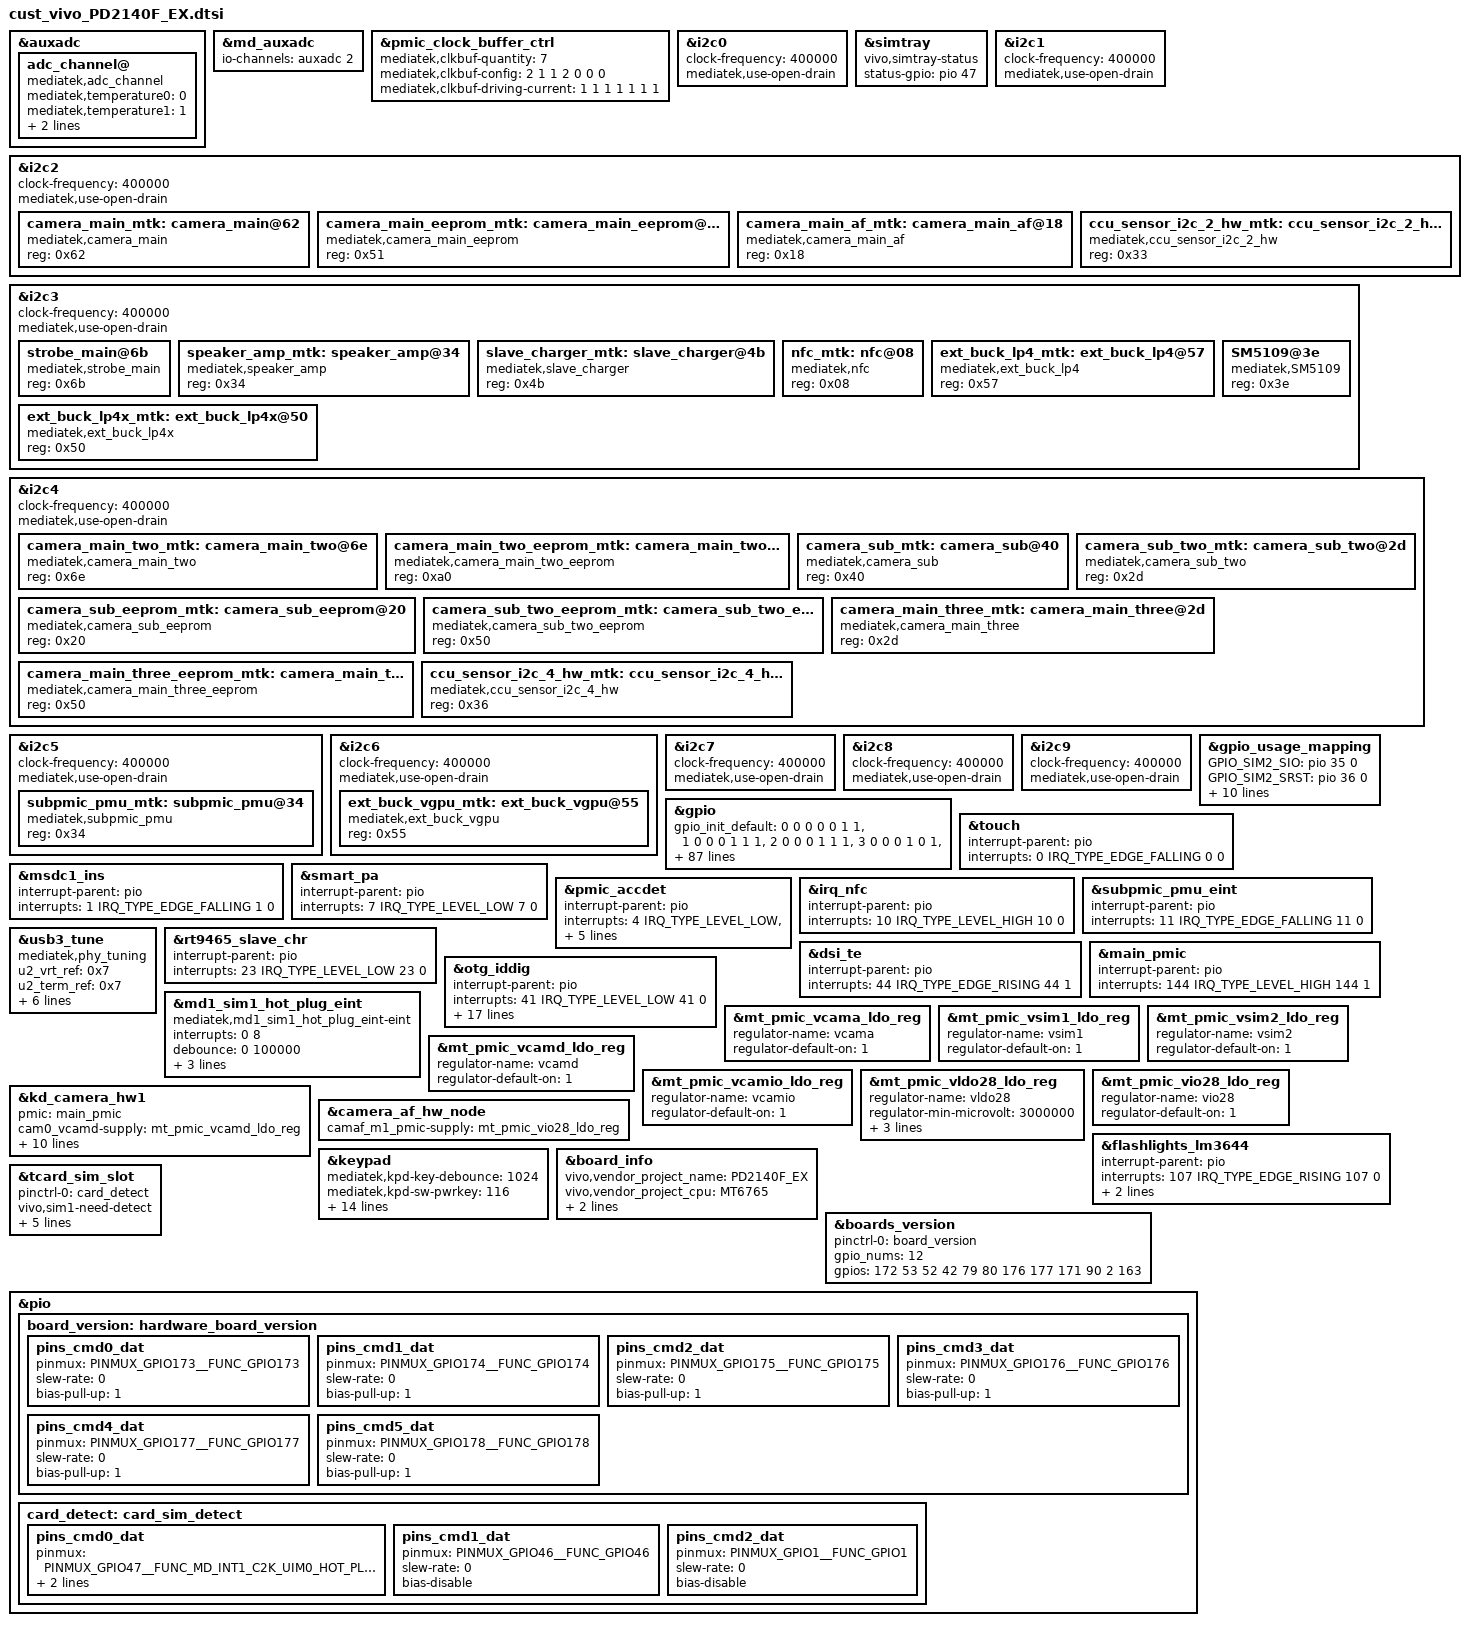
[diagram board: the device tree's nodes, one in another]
/*
 * Generated by MTK SP DrvGen Version: 3.5.160809 for MT6765.
 * 2020-11-06 15:12:15
 * Do Not Modify The File.
 * Copyright Mediatek Inc. (c) 2016.
*/

/*************************
 * ADC DTSI File
*************************/

&auxadc {
	adc_channel@ {
		compatible = "mediatek,adc_channel";
		mediatek,temperature0 = <0>;
		mediatek,temperature1 = <1>;
		mediatek,adc_fdd_rf_params_dynamic_custom_ch = <2>;
		status = "okay";
	};
};
&md_auxadc {
	io-channels = <&auxadc 2>;
};


/*************************
 * CLK_BUF DTSI File
*************************/

&pmic_clock_buffer_ctrl {
	mediatek,clkbuf-quantity = <7>;
	mediatek,clkbuf-config = <2 1 1 2 0 0 0>;
	mediatek,clkbuf-driving-current = <1 1 1 1 1 1 1>;
	status = "okay";
};


/*************************
 * I2C DTSI File
*************************/

&i2c0 {
	#address-cells = <1>;
	#size-cells = <0>;
	clock-frequency = <400000>;
	mediatek,use-open-drain;
};
&simtray {
	compatible = "vivo,simtray-status";
	status-gpio = <&pio 47 0x00>;
};
&i2c1 {
	#address-cells = <1>;
	#size-cells = <0>;
	clock-frequency = <400000>;
	mediatek,use-open-drain;
};

&i2c2 {
	#address-cells = <1>;
	#size-cells = <0>;
	clock-frequency = <400000>;
	mediatek,use-open-drain;
/*	camera_main_mtk:camera_main@46 {
		compatible = "mediatek,camera_main";
		reg = <0x46>;
		status = "okay";
	};
*/
	camera_main_mtk:camera_main@62 {
		compatible = "mediatek,camera_main";
		reg = <0x62>;
		status = "okay";
	};

	camera_main_eeprom_mtk:camera_main_eeprom@51 {
		compatible = "mediatek,camera_main_eeprom";
		reg = <0x51>;
		status = "okay";
	};
	camera_main_af_mtk:camera_main_af@18 {
		compatible = "mediatek,camera_main_af";
		reg = <0x18>;
		status = "okay";
	};

	ccu_sensor_i2c_2_hw_mtk:ccu_sensor_i2c_2_hw@33 {
		compatible = "mediatek,ccu_sensor_i2c_2_hw";
		reg = <0x33>;
		status = "okay";
	};

};

&i2c3 {
	#address-cells = <1>;
	#size-cells = <0>;
	clock-frequency = <400000>;
	mediatek,use-open-drain;

	strobe_main@6b {
	        compatible = "mediatek,strobe_main";
	        reg = <0x6b>;
	        status = "okay";
	};

	speaker_amp_mtk:speaker_amp@34 {
		compatible = "mediatek,speaker_amp";
		reg = <0x34>;
		status = "okay";
	};

	slave_charger_mtk:slave_charger@4b {
		compatible = "mediatek,slave_charger";
		reg = <0x4b>;
		status = "okay";
	};

	nfc_mtk:nfc@08 {
		compatible = "mediatek,nfc";
		reg = <0x08>;
		status = "okay";
	};

	ext_buck_lp4_mtk:ext_buck_lp4@57 {
		compatible = "mediatek,ext_buck_lp4";
		reg = <0x57>;
		status = "okay";
	};

	ext_buck_lp4x_mtk:ext_buck_lp4x@50 {
		compatible = "mediatek,ext_buck_lp4x";
		reg = <0x50>;
		status = "okay";
	};

	SM5109@3e {
		compatible = "mediatek,SM5109";
		reg = <0x3e>;
		status = "okay";
	};

};

&i2c4 {
	#address-cells = <1>;
	#size-cells = <0>;
	clock-frequency = <400000>;
	mediatek,use-open-drain;

/*		camera_sub_mtk:camera_sub@20 {
		compatible = "mediatek,camera_sub";
		reg = <0x20>;
		status = "okay";
	};
*/
	camera_main_two_mtk:camera_main_two@6e {
		compatible = "mediatek,camera_main_two";
		reg = <0x6e>;
		status = "okay";
	};
	camera_main_two_eeprom_mtk:camera_main_two_eeprom@a0 {
		compatible = "mediatek,camera_main_two_eeprom";
		reg = <0xa0>;
		status = "okay";
	};
	/*PD2140*/
	camera_sub_mtk:camera_sub@40 {
		compatible = "mediatek,camera_sub";
		reg = <0x40>;
		status = "okay";
	};
	camera_sub_eeprom_mtk:camera_sub_eeprom@20 {
		compatible = "mediatek,camera_sub_eeprom";
		reg = <0x20>;
		status = "okay";
	};
	// camera_main_two_af_mtk:camera_main_two_af@18 {
	// 	compatible = "mediatek,camera_main_two_af";
	// 	reg = <0x18>;
	// 	status = "okay";
	// };
	camera_sub_two_mtk:camera_sub_two@2d {
		compatible = "mediatek,camera_sub_two";
		reg = <0x2d>;
		status = "okay";
	};
	camera_sub_two_eeprom_mtk:camera_sub_two_eeprom@50 {
		compatible = "mediatek,camera_sub_two_eeprom";
		reg = <0x50>;
		status = "okay";
	};
	camera_main_three_mtk:camera_main_three@2d {
		compatible = "mediatek,camera_main_three";
		reg = <0x2d>;
		status = "okay";
	};
	camera_main_three_eeprom_mtk:camera_main_three_eeprom@50 {
		compatible = "mediatek,camera_main_three_eeprom";
		reg = <0x50>;
		status = "okay";
	};
	ccu_sensor_i2c_4_hw_mtk:ccu_sensor_i2c_4_hw@36 {
		compatible = "mediatek,ccu_sensor_i2c_4_hw";
		reg = <0x36>;
		status = "okay";
	};
};

&i2c5 {
	#address-cells = <1>;
	#size-cells = <0>;
	clock-frequency = <400000>;
	mediatek,use-open-drain;
	subpmic_pmu_mtk:subpmic_pmu@34 {
		compatible = "mediatek,subpmic_pmu";
		reg = <0x34>;
		status = "okay";
	};
	/*
	swithing_charger@6a {
		compatible = "mediatek,swithing_charger";
		chg_version_gpio = <&pio 173 0>;
		reg = <0x6a>;
		status = "okay";
    };
    swithing_charger_2nd@6b {
		compatible = "mediatek,swithing_charger_2nd";
		reg = <0x6b>;
		status = "okay";
    };
    slave_charger@6b {
		compatible = "mediatek,slave_charging_bq25601d";
		pinctrl-names = "slave_chg_default", "slave_chg_enable", "slave_chg_disable";
		pinctrl-0 = <&slave_chg_pins_default>;
		pinctrl-1 = <&slave_chg_pins_enable>;
		pinctrl-2 = <&slave_chg_pins_disable>;
		slave-chg-gpio = <&pio 69 0>;
		reg = <0x6b>;
		status = "okay";
    };

	usb_type_c@4e {
		compatible = "mediatek,usb_type_c";
		reg = <0x4e>;
		status = "okay";
	};*/
};

&i2c6 {
	#address-cells = <1>;
	#size-cells = <0>;
	clock-frequency = <400000>;
	mediatek,use-open-drain;


	ext_buck_vgpu_mtk:ext_buck_vgpu@55 {
		compatible = "mediatek,ext_buck_vgpu";
		reg = <0x55>;
		status = "okay";
	};

};

&i2c7 {
	#address-cells = <1>;
	#size-cells = <0>;
	clock-frequency = <400000>;
	mediatek,use-open-drain;
};

&i2c8 {
	#address-cells = <1>;
	#size-cells = <0>;
	clock-frequency = <400000>;
	mediatek,use-open-drain;
};

&i2c9 {
	#address-cells = <1>;
	#size-cells = <0>;
	clock-frequency = <400000>;
	mediatek,use-open-drain;
};



/*************************
 * GPIO DTSI File
*************************/

&gpio_usage_mapping {
	GPIO_SIM2_SIO = <&pio 35 0>;
	GPIO_SIM2_SRST = <&pio 36 0>;
	GPIO_SIM2_SCLK = <&pio 37 0>;
	GPIO_SIM1_SCLK = <&pio 38 0>;
	GPIO_SIM1_SRST = <&pio 39 0>;
	GPIO_SIM1_SIO = <&pio 40 0>;
	GPIO_SIM1_HOT_PLUG = <&pio 47 0>;
	GPIO_FDD_BAND_SUPPORT_DETECT_1ST_PIN = <&pio 172 0>;
	GPIO_FDD_BAND_SUPPORT_DETECT_2ND_PIN = <&pio 53 0>;
	GPIO_FDD_BAND_SUPPORT_DETECT_3RD_PIN = <&pio 52 0>;
	GPIO_FDD_BAND_SUPPORT_DETECT_4TH_PIN = <&pio 42 0>;
};

&gpio{
	gpio_init_default = <0 0 0 0 0 1 1>,
		<1 0 0 0 1 1 1>,
		<2 0 0 0 1 1 1>,
		<3 0 0 0 1 0 1>,
		<4 5 0 0 1 1 0>,
		<5 0 0 0 1 0 0>,
		<6 0 1 0 0 0 0>,
		<7 0 0 0 1 1 0>,
		<8 0 0 0 0 0 1>,
		<9 0 0 0 1 1 0>,
		<10 0 0 0 0 0 1>,
		<11 0 0 0 1 1 0>,
		<12 0 0 0 1 1 0>,
		<13 3 0 0 1 1 0>,
		<14 3 1 0 0 0 0>,
		<15 3 1 0 0 0 0>,
		<16 3 1 0 0 0 0>,
		<17 2 0 0 1 0 0>,
		<18 2 0 0 1 0 0>,
		<19 2 0 0 1 0 0>,
		<20 2 0 0 1 0 0>,
		<21 1 0 0 1 0 0>,
		<22 1 0 0 1 0 0>,
		<23 1 1 0 0 0 0>,
		<24 1 0 0 0 0 0>,
		<25 0 1 0 0 0 0>,
		<26 0 1 0 0 0 0>,
		<27 0 1 0 0 0 0>,
		<28 0 1 0 0 0 0>,
		<29 1 1 0 0 0 1>,
		<30 1 0 0 1 1 1>,
		<31 1 0 0 1 1 1>,
		<32 1 0 0 1 1 1>,
		<33 1 0 0 1 1 1>,
		<34 1 0 0 1 1 1>,
		<35 1 0 0 1 1 0>,
		<36 1 1 0 0 0 0>,
		<37 1 1 0 0 0 0>,
		<38 1 1 0 0 0 0>,
		<39 1 1 0 0 0 0>,
		<40 1 0 0 1 1 0>,
		<41 0 0 0 1 1 0>,
		<42 0 0 0 1 1 0>,
		<43 1 1 0 0 0 0>,
		<44 1 0 0 1 0 0>,
		<45 0 1 0 0 0 0>,
		<46 0 0 0 0 0 0>,
		<47 1 0 0 0 0 0>,
		<48 1 0 0 1 1 1>,
		<49 1 0 0 1 1 1>,
		<50 1 0 0 1 1 1>,
		<51 1 0 0 1 1 1>,
		<52 0 0 0 1 1 0>,
		<53 0 0 0 1 1 0>,
		<54 0 0 0 0 0 1>,
		<55 1 1 0 1 0 0>,
		<56 1 1 0 1 0 0>,
		<57 1 1 0 1 0 0>,
		<58 0 0 0 1 0 0>,
		<59 1 0 0 1 0 0>,
		<60 1 0 0 1 0 0>,
		<61 1 0 0 1 0 0>,
		<62 1 0 0 1 0 0>,
		<63 1 0 0 1 0 0>,
		<64 1 0 0 1 0 0>,
		<65 1 0 0 1 0 0>,
		<66 1 0 0 1 0 0>,
		<67 1 0 0 1 0 0>,
		<68 1 0 0 1 0 0>,
		<69 1 1 0 1 0 0>,
		<70 1 1 0 1 0 0>,
		<71 1 1 0 1 0 0>,
		<72 1 1 0 1 0 0>,
		<73 1 1 0 1 0 0>,
		<74 1 1 0 1 0 0>,
		<75 1 1 0 1 0 0>,
		<76 1 1 0 1 0 0>,
		<77 1 1 0 1 0 0>,
		<78 1 1 0 1 0 0>,
		<79 1 0 0 1 0 0>,
		<80 1 0 0 1 0 0>,
		<81 1 0 0 1 1 1>,
		<82 1 0 0 1 1 1>,
		<83 1 0 0 1 1 1>,
		<84 1 0 0 1 1 1>,
		<85 1 1 0 1 0 0>,
		<86 1 1 0 1 0 0>,
		<87 0 1 0 0 0 0>,
		<88 0 0 0 1 0 0>,
		<89 1 0 0 1 0 0>,
		<90 2 1 0 0 0 0>,
		<91 0 1 0 1 0 0>,
		<92 1 1 0 0 0 0>,
		<93 1 0 0 1 1 0>,
		<94 0 0 0 1 0 0>,
		<95 1 0 0 1 1 0>,
		<96 1 1 0 0 0 0>,
		<97 0 1 0 0 0 0>,
		<98 0 1 0 0 0 0>,
		<99 0 1 0 0 0 0>,
		<100 0 1 0 0 0 0>,
		<101 0 1 0 0 0 0>,
		<102 0 1 0 0 0 0>,
		<103 1 0 0 1 1 1>,
		<104 1 0 0 1 1 1>,
		<105 1 0 0 1 1 1>,
		<106 1 0 0 1 1 1>,
		<107 2 1 0 0 0 0>,
		<108 0 1 0 0 0 0>,
		<109 0 1 0 0 0 0>,
		<110 0 0 0 1 0 0>,
		<111 0 0 0 1 0 0>,
		<112 0 0 0 1 0 0>,
		<113 0 0 0 1 0 0>,
		<114 0 0 0 1 0 0>,
		<115 0 0 0 1 0 0>,
		<116 0 0 0 1 0 0>,
		<117 0 0 0 1 0 0>,
		<118 0 0 0 1 0 0>,
		<119 0 0 0 1 0 0>,
		<120 0 0 0 1 0 0>,
		<121 0 0 0 1 0 0>,
		<122 1 0 0 1 1 1>,
		<123 1 0 0 1 1 1>,
		<124 1 1 0 0 0 1>,
		<125 1 0 0 1 1 1>,
		<126 1 0 0 1 1 1>,
		<127 1 0 0 1 1 1>,
		<128 1 0 0 1 1 1>,
		<129 1 0 0 1 1 1>,
		<130 1 0 0 1 1 1>,
		<131 1 0 0 1 0 1>,
		<132 1 0 0 1 1 1>,
		<133 1 1 1 0 0 1>,
		<134 1 0 0 1 0 1>,
		<135 1 1 0 0 0 0>,
		<136 1 1 0 0 0 0>,
		<137 1 1 0 0 0 0>,
		<138 1 1 0 0 0 0>,
		<139 1 1 0 0 0 0>,
		<140 1 0 0 1 0 0>,
		<141 1 0 0 1 0 0>,
		<142 1 0 0 1 0 0>,
		<143 1 0 0 1 0 0>,
		<144 1 0 0 1 0 0>,
		<145 1 1 1 0 0 0>,
		<146 1 0 0 1 0 0>,
		<147 1 1 0 0 0 0>,
		<148 1 1 0 0 0 0>,
		<149 1 1 0 0 0 0>,
		<150 0 1 0 0 0 0>,
		<151 0 1 0 0 0 0>,
		<152 0 1 0 0 0 0>,
		<153 0 1 0 0 0 0>,
		<154 0 1 1 0 0 0>,
		<155 0 1 0 0 0 0>,
		<156 0 1 0 0 0 0>,
		<157 0 1 0 0 0 0>,
		<158 7 0 0 1 0 0>,
		<159 0 1 0 0 0 0>,
		<160 0 1 0 0 0 0>,
		<161 1 0 0 1 1 1>,
		<162 1 0 0 1 1 1>,
		<163 0 0 0 0 0 0>,
		<164 0 0 0 0 0 0>,
		<165 0 1 0 1 0 0>,
		<166 0 1 0 1 0 0>,
		<167 0 1 0 0 0 0>,
		<168 0 0 0 1 0 0>,
		<169 0 1 0 0 0 0>,
		<170 0 1 0 0 0 0>,
		<171 0 0 0 1 0 0>,
		<172 0 0 0 1 1 0>,
		<173 0 1 0 0 0 0>,
		<174 0 0 0 1 1 0>,
		<175 0 0 0 1 1 0>,
		<176 0 0 0 1 1 0>,
		<177 0 0 0 1 1 0>,
		<178 0 1 0 0 0 0>,
		<179 0 0 0 1 0 0>;
};


/*************************
 * EINT DTSI File
*************************/

#include <dt-bindings/interrupt-controller/irq.h>
#include <dt-bindings/interrupt-controller/arm-gic.h>

&touch {
	interrupt-parent = <&pio>;
	interrupts = <0 IRQ_TYPE_EDGE_FALLING 0 0>;
	status = "okay";
};

&msdc1_ins {
	interrupt-parent = <&pio>;
	interrupts = <1 IRQ_TYPE_EDGE_FALLING 1 0>;
	status = "okay";
};

#if 0 //add for fix boot failed in lk during the bringup stage
&mrdump_ext_rst {
	interrupt-parent = <&pio>;
	interrupts = <2 IRQ_TYPE_LEVEL_LOW 2 0>;
	deb-gpios = <&pio 2 0>;
	debounce = <512000>;
	status = "okay";
};
#endif

&smart_pa {
	interrupt-parent = <&pio>;
	interrupts = <7 IRQ_TYPE_LEVEL_LOW 7 0>;
	status = "okay";
};

&pmic_accdet {
	interrupt-parent = <&pio>;
	interrupts = <4 IRQ_TYPE_LEVEL_LOW>,
				 <3 IRQ_TYPE_LEVEL_LOW>;
	deb-gpios = <&pio 4 0>;
	deb-rgpios = <&pio 3 0>;
	debounce = <256000>;
	debounce1 = <256000>;
	status = "okay";
};

&irq_nfc {
	interrupt-parent = <&pio>;
	interrupts = <10 IRQ_TYPE_LEVEL_HIGH 10 0>;
	status = "okay";
};

&subpmic_pmu_eint {
	interrupt-parent = <&pio>;
	interrupts = <11 IRQ_TYPE_EDGE_FALLING 11 0>;
	status = "okay";
};

/*taozongchen add for usb start */
&usb3_tune {
	compatible = "mediatek,phy_tuning";
	u2_vrt_ref = <0x7>;
	u2_term_ref = <0x7>;
	u2_hstx_srctrl = <0x4>;
	u2_enhance = <0x3>;
	u2_vrt_ref_host = <0x4>;
	u2_term_ref_host = <0x3>;
	u2_hstx_srctrl_host = <0x4>;
	u2_enhance_host = <0x2>;
	status = "okay";
};
/* taozongchen add for usb end */

&rt9465_slave_chr {
	interrupt-parent = <&pio>;
	interrupts = <23 IRQ_TYPE_LEVEL_LOW 23 0>;
	status = "okay";
};

&dsi_te {
	interrupt-parent = <&pio>;
	interrupts = <44 IRQ_TYPE_EDGE_RISING 44 1>;
	status = "okay";
};

&main_pmic {
	interrupt-parent = <&pio>;
	interrupts = <144 IRQ_TYPE_LEVEL_HIGH 144 1>;
	status = "okay";
};

&otg_iddig {
	interrupt-parent = <&pio>;
	interrupts = <41 IRQ_TYPE_LEVEL_LOW 41 0>;
	/*debounce = <110 0>;*/
	usbid-num = <&pio 41 1>;
	mtk,otg_chip_compatible_mode;
	usbid2-num = <&pio 167 1>;
	platform-id = <&pio 171 1>;
	pinctrl-names = "iddig_default", "iddig_otg_gpio", "iddig_otg_gpio_pull_down", "otg_gpio_pull_high", "otg_gpio_pull_low", "otg_gpio_pull_in", "otg_gpio_pull1_high", "otg_gpio_pull1_low", "otg_gpio_pull1_in", "iddig_otg_init",
"otg_gpio167_pull_high", "otg_gpio167_pull_low", "otg_gpio167_pull_in";
	pinctrl-0 = <&iddig_default>;
	pinctrl-1 = <&gpio41_mode0_gpio>;
	pinctrl-2 = <&gpio41_mode0_gpio_pull_down>;
	pinctrl-3 = <&gpio165_otg_pull_high>;
	pinctrl-4 = <&gpio165_otg_pull_low>;
	pinctrl-5 = <&gpio165_otg_pull_in>;
	pinctrl-6 = <&gpio164_otg_pull1_high>;
	pinctrl-7 = <&gpio164_otg_pull1_low>;
	pinctrl-8 = <&gpio164_otg_pull1_in>;
	pinctrl-9 = <&gpio41_mode1_iddig>;

	pinctrl-10 = <&gpio167_otg_pull1_high>;
	pinctrl-11 = <&gpio167_otg_pull1_low>;
	pinctrl-12 = <&gpio167_otg_pull1_in>;
	status = "okay";
};

/*************************
 * MD1_EINT DTSI File
*************************/

&md1_sim1_hot_plug_eint {
	compatible = "mediatek,md1_sim1_hot_plug_eint-eint";
	interrupts = <0 8>;
	debounce = <0 100000>;
	dedicated = <0 0>;
	src_pin = <0 1>;
	sockettype = <0 0>;
	status = "okay";
};



/*************************
 * PMIC DTSI File
*************************/

&mt_pmic_vcama_ldo_reg {
	regulator-name = "vcama";
	regulator-default-on = <1>; /* 0:skip, 1: off, 2:on */
	status = "okay";
};
&mt_pmic_vsim1_ldo_reg {
	regulator-name = "vsim1";
	regulator-default-on = <1>; /* 0:skip, 1: off, 2:on */
	status = "okay";
};
&mt_pmic_vsim2_ldo_reg {
	regulator-name = "vsim2";
	regulator-default-on = <1>; /* 0:skip, 1: off, 2:on */
	status = "okay";
};
&mt_pmic_vcamd_ldo_reg {
	regulator-name = "vcamd";
	regulator-default-on = <1>; /* 0:skip, 1: off, 2:on */
	status = "okay";
};
&mt_pmic_vcamio_ldo_reg {
	regulator-name = "vcamio";
	regulator-default-on = <1>; /* 0:skip, 1: off, 2:on */
	status = "okay";
};
&mt_pmic_vldo28_ldo_reg {
	regulator-name = "vldo28";
	regulator-min-microvolt = <3000000>;
	regulator-max-microvolt = <3000000>;
	//regulator-default-on = <2>; /* 0:skip, 1: off, 2:on */
	regulator-always-on;
	regulator-boot-on;
	status = "okay";
};
&mt_pmic_vio28_ldo_reg {
	regulator-name = "vio28";
	regulator-default-on = <1>; /* 0:skip, 1: off, 2:on */
	status = "okay";
};

&kd_camera_hw1 {
	pmic = <&main_pmic>;
	cam0_vcamd-supply = <&mt_pmic_vcamd_ldo_reg>;
	cam0_vcamio-supply = <&mt_pmic_vcamio_ldo_reg>;


	cam1_vcamd-supply= <&mt_pmic_vcamd_ldo_reg>;
	cam1_vcamio-supply= <&mt_pmic_vcamio_ldo_reg>;
	/*wayoung need to check*/
	cam2_vcamio-supply= <&mt_pmic_vcamio_ldo_reg>; //checked

/*	cam3_vcamd-supply= <&mt_pmic_vcamd_ldo_reg>;
	cam3_vcamio-supply= <&mt_pmic_vcamio_ldo_reg>;*/

	cam0_enable_sensor = "hi1336qtechpd2140main_mipi_raw hi1336sunnypd2140main_mipi_raw gc08a3qtepd2140main_mipi_raw gc08a3sunpd2140main_mipi_raw imx258qtepd2140main_mipi_raw";
	cam1_enable_sensor = "hi556lcepd2140front_mipi_raw gc5035txdpd2140front_mipi_raw gc5035hltpd2140front_mipi_raw gc08a3qtepd2140front_mipi_raw gc08a3sunpd2140front_mipi_raw imx355sunpd2140front_mipi_raw";
	cam2_enable_sensor = "gc02m1pd2140_mipi_raw ov02b10lcepd2140macro_mipi_raw gc02m1hltpd2140macro_mipi_raw";
/*	cam3_enable_sensor = "ov02b10_mipi_raw";*/
	status = "okay";

};
/*hope add main af pmic power start*/
&camera_af_hw_node {
	camaf_m1_pmic-supply = <&mt_pmic_vio28_ldo_reg>;
};
/*hope add main af pmic power end*/


/*hope add flashlight lm3644 for flash irq start */

&flashlights_lm3644 {
	interrupt-parent = <&pio>;
	interrupts = <107 IRQ_TYPE_EDGE_RISING 107 0>;
	deb-gpios = <&pio 107 0>;
	debounce = <256000>;
	status = "okay";
};

/*hope add flashlight lm3644 for flash irq end */


/*
&touch {
	vtouch-supply = <&mt_pmic_vldo28_ldo_reg>;
	status = "okay";
};
*/

/*************************
 * POWER DTSI File
*************************/



/*************************
 * KPD DTSI File
*************************/

&keypad {
	mediatek,kpd-key-debounce = <1024>;
	mediatek,kpd-sw-pwrkey = <116>;
	mediatek,kpd-hw-pwrkey = <8>;
	mediatek,kpd-sw-rstkey  = <115>;
	mediatek,kpd-hw-rstkey = <17>;
	mediatek,kpd-use-extend-type = <0>;
	/*HW Keycode [0~71] -> Linux Keycode*/
	mediatek,kpd-hw-map-num = <72>;
	mediatek,kpd-hw-init-map = <115 0 0 0 0 0 0 0 0 0 0 0 0 0 0 0 0 0 0 0 0 0 0 0 0 0 0 0 0 0 0 0 0 0 0 0 0 0 0 0 0 0 0 0 0 0 0 0 0 0 0 0 0 0 0 0 0 0 0 0 0 0 0 0 0 0 0 0 0 0 0 0 >;
	mediatek,kpd-pwrkey-eint-gpio = <0>;
	mediatek,kpd-pwkey-gpio-din  = <0>;
	mediatek,kpd-hw-dl-key0 = <17>;
	mediatek,kpd-hw-dl-key1 = <0>;
	mediatek,kpd-hw-dl-key2 = <8>;
	mediatek,kpd-hw-recovery-key = <17>;
	mediatek,kpd-hw-factory-key = <0>;
	status = "okay";
};

/* add board info fdt node by corebsp begin */
&board_info {
	vivo,vendor_project_name = "PD2140F_EX";
	vivo,vendor_project_cpu = "MT6765";
	vivo,vendor_project_freq = "2.3";
	vivo,vendor_project_cpunum = <8>;
};
&boards_version {
	pinctrl-names = "default";
	pinctrl-0 = <&board_version>;
	gpio_nums = <12>;
	gpios = <172 53 52 42 79 80 176 177 171 90 2 163>;


};



&tcard_sim_slot {	
	pinctrl-names = "default";
	pinctrl-0 = <&card_detect>;
	vivo,sim1-need-detect;
	vivo,sim2-need-detect;
	vivo,sim1-detect-high;
	vivo,sim2-detect-high;

	card-detect-sim1,gpios = <&pio 47 0x0>;
	card-detect-sim2,gpios = <&pio 47 0x0>;
	//card-detect-tf-card,gpios = <&pio 1 0x0>;
};


&pio {
	board_version: hardware_board_version {
		pins_cmd0_dat {
			pinmux = <PINMUX_GPIO173__FUNC_GPIO173>;
			slew-rate = <0>;
			bias-pull-up = <1>;
		};
		pins_cmd1_dat {
			pinmux = <PINMUX_GPIO174__FUNC_GPIO174>;
			slew-rate = <0>;
			bias-pull-up = <1>;
		};
		pins_cmd2_dat {
			pinmux = <PINMUX_GPIO175__FUNC_GPIO175>;
			slew-rate = <0>;
			bias-pull-up = <1>;
		};
		pins_cmd3_dat {
			pinmux = <PINMUX_GPIO176__FUNC_GPIO176>;
			slew-rate = <0>;
			bias-pull-up = <1>;
		};
		pins_cmd4_dat {
			pinmux = <PINMUX_GPIO177__FUNC_GPIO177>;
			slew-rate = <0>;
			bias-pull-up = <1>;
		};
		pins_cmd5_dat {
			pinmux = <PINMUX_GPIO178__FUNC_GPIO178>;
			slew-rate = <0>;
			bias-pull-up = <1>;
		};
	};

	card_detect: card_sim_detect {
		pins_cmd0_dat {
			pinmux = <PINMUX_GPIO47__FUNC_MD_INT1_C2K_UIM0_HOT_PLUG>;
			slew-rate = <0>;
			bias-disable;
		};
		pins_cmd1_dat {
			pinmux = <PINMUX_GPIO46__FUNC_GPIO46>;
			slew-rate = <0>;
			bias-disable;
		};
		pins_cmd2_dat {
			pinmux = <PINMUX_GPIO1__FUNC_GPIO1>;
			slew-rate = <0>;
			bias-disable;
		};
	};
};
/* add board info fdt node by corebsp end */
